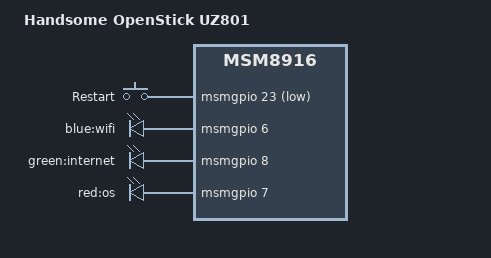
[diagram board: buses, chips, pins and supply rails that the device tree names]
// SPDX-License-Identifier: GPL-2.0-only
/*
 * Copyright (C) 2021-2022 HandsomeYingyan <handsomeyingyan@gmail.com>
 *
 */
 
/dts-v1/;
#include "msm8916-handsome-openstick-common.dtsi"

/ {
	model = "Handsome OpenStick UZ801";
	compatible = "handsome,openstick", "qcom,msm8916";

	gpio-keys {
		compatible = "gpio-keys";
		#address-cells = <1>;
		#size-cells = <0>;
		autorepeat;

		pinctrl-names = "default";
		pinctrl-0 = <&gpio_keys_default>;
		label = "GPIO Buttons";

		reset {
			label = "Restart";
			gpios = <&msmgpio 23 GPIO_ACTIVE_LOW>;
			linux,code = <KEY_RESTART>;
		};
	};

	leds {
		pinctrl-names = "default";
		pinctrl-0 = <&msmgpio_leds>;

		compatible = "gpio-leds";

		wifi {
			label = "blue:wifi";
			gpios = <&msmgpio 6 GPIO_ACTIVE_HIGH>;
			linux,default-trigger = "phy0tx";
			default-state = "off";
		};

		led_internet: internet {
			label = "green:internet";
			gpios = <&msmgpio 8 GPIO_ACTIVE_HIGH>;
			default-state = "off";
		};

		os {
			label = "red:os";
			gpios = <&msmgpio 7 GPIO_ACTIVE_HIGH>;
			linux,default-trigger = "heartbeat";
			default-state = "on";
		};

	};
};

&msmgpio {
	msmgpio_leds: msmgpio-leds {
		pins = "gpio6","gpio7","gpio8";
		function = "gpio";

		bias-disabled;
	};

	gpio_keys_default: gpio_keys_default {
		pins = "gpio23";
		function = "gpio";

		drive-strength = <8>;
		input-enable;
		bias-pull-up;
	};
};
